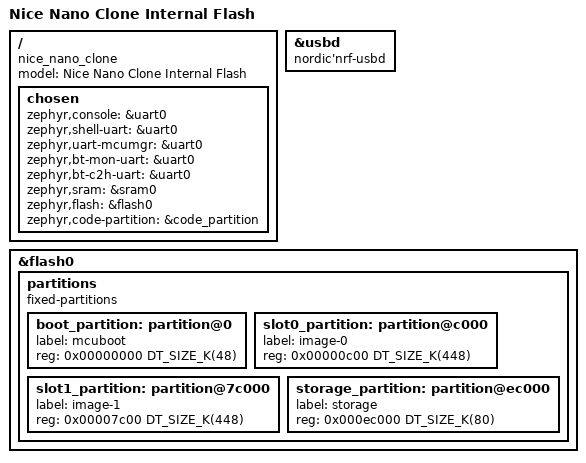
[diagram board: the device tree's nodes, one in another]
/dts-v1/;
#include <nordic/nrf52840_qiaa.dtsi>

/ {
        model = "Nice Nano Clone Internal Flash";
        compatible = "nice_nano_clone", "nordic,nrf52840-qiaa", "nordic,nrf52840";

        chosen {
                zephyr,console = &uart0;
                zephyr,shell-uart = &uart0;
                zephyr,uart-mcumgr = &uart0;
                zephyr,bt-mon-uart = &uart0;
                zephyr,bt-c2h-uart = &uart0;
                zephyr,sram = &sram0;
                zephyr,flash = &flash0;
                zephyr,code-partition = &code_partition;
        };
};

&usbd {
        status = "okay";
};

zephyr_udc0: &usbd {
        compatible = "nordic'nrf-usbd";
        status = "okay";
};

&flash0 {
        partitions {
                compatible = "fixed-partitions";
                #address-cells = <1>;
                #size-cells = <1>;

                boot_partition: partition@0 {
                        label = "mcuboot";
                        reg = <0x00000000 DT_SIZE_K(48)>;
                };
                slot0_partition: partition@c000 {
                        label = "image-0";
                        reg = <0x00000c00 DT_SIZE_K(448)>;
                };
                slot1_partition: partition@7c000 {
                        label = "image-1";
                        reg = <0x00007c00 DT_SIZE_K(448)>;
                };
                storage_partition: partition@ec000 {
                        label = "storage";
                        reg = <0x000ec000 DT_SIZE_K(80)>;
                };
        };
};
